AUTOSAR XML (schema 4-2-2)
package /ComponentTypes
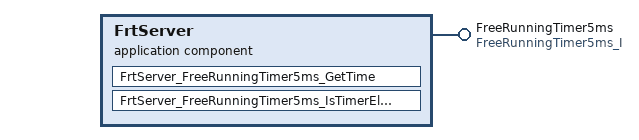
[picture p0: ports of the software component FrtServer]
  application sw component type FrtServer
    provide port FreeRunningTimer5ms: provided-com-specs=[{operation=GetTime, queue-length=1}, {operation=IsTimerElapsed, queue-length=1}], provided-interface=FreeRunningTimer5ms_I
    behavior FrtServer_InternalBehavior: port-api-option{enable-take-address=false, indirect-api=false, port=FreeRunningTimer5ms}
      operation invoked event OIT_FrtServer_FreeRunningTimer5ms_GetTime_FreeRunningTimer5ms_GetTime: start-on-event=FrtServer_FreeRunningTimer5ms_GetTime, operation=FreeRunningTimer5ms.GetTime
      operation invoked event OIT_FrtServer_FreeRunningTimer5ms_IsTimerElapsed_FreeRunningTimer5ms_IsTimerElapsed: start-on-event=FrtServer_FreeRunningTimer5ms_IsTimerElapsed, operation=FreeRunningTimer5ms.IsTimerElapsed
      runnable FrtServer_FreeRunningTimer5ms_GetTime
      runnable FrtServer_FreeRunningTimer5ms_IsTimerElapsed
  swc implementation FrtServer_Implementation: behavior=FrtServer_InternalBehavior
    code-descriptors:
      code Default: artifact-descriptors=autosar-engineering-object={short-label=Default, category=SWSRC}
